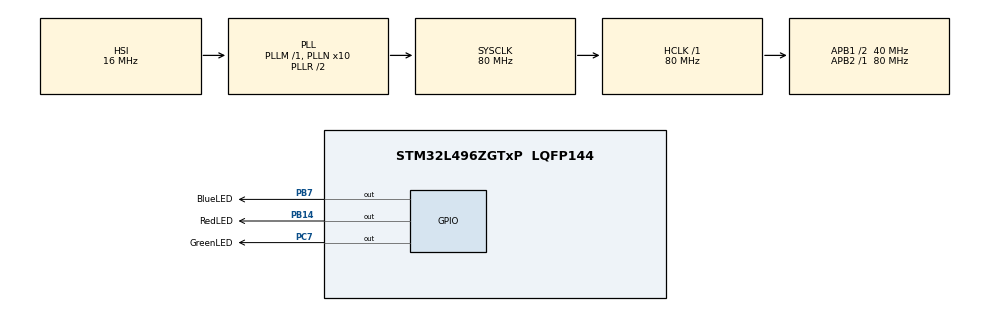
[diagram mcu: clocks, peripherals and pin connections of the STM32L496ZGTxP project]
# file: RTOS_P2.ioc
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FREERTOS.Tasks01=Task1,8,128,StartTask1,Default,NULL,Dynamic,NULL,NULL;Task2,16,128,StartTask2,Default,NULL,Dynamic,NULL,NULL;Task3,24,128,StartTask3,Default,NULL,Dynamic,NULL,NULL;Task4,32,128,StartTask4,Default,NULL,Dynamic,NULL,NULL
FREERTOS.configUSE_NEWLIB_REENTRANT=1
Mcu.Family=STM32L4
Mcu.Name=STM32L496ZGTxP
Mcu.Package=LQFP144
NVIC.PriorityGroup=NVIC_PRIORITYGROUP_4
NVIC.TIM6_DAC_IRQn=true\:15\:0\:false\:false\:true\:false\:false\:true\:true
NVIC.TimeBase=TIM6_DAC_IRQn
NVIC.TimeBaseIP=TIM6
PA13\ (JTMS/SWDIO).Mode=Serial_Wire
PA13\ (JTMS/SWDIO).Signal=SYS_JTMS-SWDIO
PA14\ (JTCK/SWCLK).Mode=Serial_Wire
PA14\ (JTCK/SWCLK).Signal=SYS_JTCK-SWCLK
PB14.GPIO_Label=RedLED
PB14.Signal=GPIO_Output
PB7.GPIO_Label=BlueLED
PB7.Signal=GPIO_Output
PC7.GPIO_Label=GreenLED
PC7.Signal=GPIO_Output
ProjectManager.HeapSize=0x200
ProjectManager.StackSize=0x400
ProjectManager.TargetToolchain=STM32CubeIDE
RCC.48MHZClocksFreq_Value=24000000
RCC.ADCFreq_Value=64000000
RCC.AHBFreq_Value=80000000
RCC.APB1CLKDivider=RCC_HCLK_DIV2
RCC.APB1Freq_Value=40000000
RCC.APB1TimFreq_Value=80000000
RCC.APB2Freq_Value=80000000
RCC.APB2TimFreq_Value=80000000
RCC.CortexFreq_Value=80000000
RCC.HCLKFreq_Value=80000000
RCC.HSE_VALUE=8000000
RCC.HSI48_VALUE=48000000
RCC.HSI_VALUE=16000000
RCC.LSE_VALUE=32768
RCC.MSI_VALUE=4000000
RCC.PLLMUL=RCC_PLL_MUL9
RCC.PLLN=10
RCC.PLLSourceVirtual=RCC_PLLSOURCE_HSI
RCC.PRESCALERUSB=RCC_USBCLKSOURCE_PLL_DIV1_5
RCC.SYSCLKFreq_VALUE=80000000
RCC.SYSCLKSource=RCC_SYSCLKSOURCE_PLLCLK
RCC.SYSCLKSourceVirtual=RCC_SYSCLKSOURCE_PLLCLK
RCC.USBFreq_Value=64000000
RCC.VCOOutputFreq_Value=160000000
VP_FREERTOS_VS_CMSIS_V2.Mode=CMSIS_V2
VP_SYS_VS_tim6.Mode=TIM6
board=NUCLEO-L496ZG-P

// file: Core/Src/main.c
/* USER CODE BEGIN Header */
/**
  ******************************************************************************
  * @file           : main.c
  * @brief          : Main program body
  ******************************************************************************
  * @attention
  *
  * Copyright (c) 2026 STMicroelectronics.
  * All rights reserved.
  *
  * This software is licensed under terms that can be found in the LICENSE file
  * in the root directory of this software component.
  * If no LICENSE file comes with this software, it is provided AS-IS.
  *
  ******************************************************************************
  */
/* USER CODE END Header */
#include "main.h"
#include "cmsis_os.h"

/* Definitions for Task1 */
osThreadId_t Task1Handle;
const osThreadAttr_t Task1_attributes = {
  .name = "Task1",
  .stack_size = 128 * 4,
  .priority = (osPriority_t) osPriorityLow,
};
/* Definitions for Task2 */
osThreadId_t Task2Handle;
const osThreadAttr_t Task2_attributes = {
  .name = "Task2",
  .stack_size = 128 * 4,
  .priority = (osPriority_t) osPriorityBelowNormal,
};
/* Definitions for Task3 */
osThreadId_t Task3Handle;
const osThreadAttr_t Task3_attributes = {
  .name = "Task3",
  .stack_size = 128 * 4,
  .priority = (osPriority_t) osPriorityNormal,
};
/* Definitions for Task4 */
osThreadId_t Task4Handle;
const osThreadAttr_t Task4_attributes = {
  .name = "Task4",
  .stack_size = 128 * 4,
  .priority = (osPriority_t) osPriorityAboveNormal,
};

void SystemClock_Config(void);
static void MX_GPIO_Init(void);
void StartTask1(void *argument);
void StartTask2(void *argument);
void StartTask3(void *argument);
void StartTask4(void *argument);

int main(void)
{

  /* MCU Configuration--------------------------------------------------------*/

  /* Reset of all peripherals, Initializes the Flash interface and the Systick. */
  HAL_Init();

  /* Configure the system clock */
  SystemClock_Config();

  /* Initialize all configured peripherals */
  MX_GPIO_Init();

  /* Init scheduler */
  osKernelInitialize();

  /* Create the thread(s) */
  /* creation of Task1 */
  Task1Handle = osThreadNew(StartTask1, NULL, &Task1_attributes);

  /* creation of Task2 */
  Task2Handle = osThreadNew(StartTask2, NULL, &Task2_attributes);

  /* creation of Task3 */
  Task3Handle = osThreadNew(StartTask3, NULL, &Task3_attributes);

  /* creation of Task4 */
  Task4Handle = osThreadNew(StartTask4, NULL, &Task4_attributes);

  /* Start scheduler */
  osKernelStart();

  /* We should never get here as control is now taken by the scheduler */

  /* Infinite loop */
  while (1)
  {

  }
}

void SystemClock_Config(void)
{
  RCC_OscInitTypeDef RCC_OscInitStruct = {0};
  RCC_ClkInitTypeDef RCC_ClkInitStruct = {0};

  /** Configure the main internal regulator output voltage
  */
  if (HAL_PWREx_ControlVoltageScaling(PWR_REGULATOR_VOLTAGE_SCALE1) != HAL_OK)
  {
    Error_Handler();
  }

  /** Initializes the RCC Oscillators according to the specified parameters
  * in the RCC_OscInitTypeDef structure.
  */
  RCC_OscInitStruct.OscillatorType = RCC_OSCILLATORTYPE_HSI;
  RCC_OscInitStruct.HSIState = RCC_HSI_ON;
  RCC_OscInitStruct.HSICalibrationValue = RCC_HSICALIBRATION_DEFAULT;
  RCC_OscInitStruct.PLL.PLLState = RCC_PLL_ON;
  RCC_OscInitStruct.PLL.PLLSource = RCC_PLLSOURCE_HSI;
  RCC_OscInitStruct.PLL.PLLM = 1;
  RCC_OscInitStruct.PLL.PLLN = 10;
  RCC_OscInitStruct.PLL.PLLP = RCC_PLLP_DIV2;
  RCC_OscInitStruct.PLL.PLLQ = RCC_PLLQ_DIV2;
  RCC_OscInitStruct.PLL.PLLR = RCC_PLLR_DIV2;
  if (HAL_RCC_OscConfig(&RCC_OscInitStruct) != HAL_OK)
  {
    Error_Handler();
  }

  /** Initializes the CPU, AHB and APB buses clocks
  */
  RCC_ClkInitStruct.ClockType = RCC_CLOCKTYPE_HCLK|RCC_CLOCKTYPE_SYSCLK
                              |RCC_CLOCKTYPE_PCLK1|RCC_CLOCKTYPE_PCLK2;
  RCC_ClkInitStruct.SYSCLKSource = RCC_SYSCLKSOURCE_PLLCLK;
  RCC_ClkInitStruct.AHBCLKDivider = RCC_SYSCLK_DIV1;
  RCC_ClkInitStruct.APB1CLKDivider = RCC_HCLK_DIV2;
  RCC_ClkInitStruct.APB2CLKDivider = RCC_HCLK_DIV1;

  if (HAL_RCC_ClockConfig(&RCC_ClkInitStruct, FLASH_LATENCY_4) != HAL_OK)
  {
    Error_Handler();
  }
}

static void MX_GPIO_Init(void)
{
  GPIO_InitTypeDef GPIO_InitStruct = {0};

  /* GPIO Ports Clock Enable */
  __HAL_RCC_GPIOB_CLK_ENABLE();
  __HAL_RCC_GPIOC_CLK_ENABLE();
  __HAL_RCC_GPIOA_CLK_ENABLE();

  /*Configure GPIO pin Output Level */
  HAL_GPIO_WritePin(GPIOB, RedLED_Pin|BlueLED_Pin, GPIO_PIN_RESET);

  /*Configure GPIO pin Output Level */
  HAL_GPIO_WritePin(GreenLED_GPIO_Port, GreenLED_Pin, GPIO_PIN_RESET);

  /*Configure GPIO pins : RedLED_Pin BlueLED_Pin */
  GPIO_InitStruct.Pin = RedLED_Pin|BlueLED_Pin;
  GPIO_InitStruct.Mode = GPIO_MODE_OUTPUT_PP;
  GPIO_InitStruct.Pull = GPIO_NOPULL;
  GPIO_InitStruct.Speed = GPIO_SPEED_FREQ_LOW;
  HAL_GPIO_Init(GPIOB, &GPIO_InitStruct);

  /*Configure GPIO pin : GreenLED_Pin */
  GPIO_InitStruct.Pin = GreenLED_Pin;
  GPIO_InitStruct.Mode = GPIO_MODE_OUTPUT_PP;
  GPIO_InitStruct.Pull = GPIO_NOPULL;
  GPIO_InitStruct.Speed = GPIO_SPEED_FREQ_LOW;
  HAL_GPIO_Init(GreenLED_GPIO_Port, &GPIO_InitStruct);

}

void StartTask1(void *argument)
{
  /* USER CODE BEGIN 5 */

  /* Infinite loop */
  for(;;)
  {
      volatile uint32_t wait = 50000000;
	  HAL_GPIO_TogglePin(RedLED_GPIO_Port, RedLED_Pin);
	  osDelay(1000);
	  while (wait--);
  }
  /* USER CODE END 5 */
}

void StartTask2(void *argument)
{
  /* USER CODE BEGIN StartTask2 */
  /* Infinite loop */
  for(;;)
  {
	  HAL_GPIO_TogglePin(BlueLED_GPIO_Port, BlueLED_Pin);
	  osDelay(500);
  }
  /* USER CODE END StartTask2 */
}

void StartTask3(void *argument)
{
  /* USER CODE BEGIN StartTask3 */
  /* Infinite loop */
  for(;;)
  {
	  volatile uint32_t wait = 50000000;
	  HAL_GPIO_TogglePin(GreenLED_GPIO_Port, GreenLED_Pin);
	  osDelay(200);
	  while (wait--);
  }
  /* USER CODE END StartTask3 */
}

void StartTask4(void *argument)
{
  /* USER CODE BEGIN StartTask4 */
  /* Infinite loop */
  for(;;)
  {
	  osDelay(1000);
	  osThreadSuspend(Task3Handle);
	  osDelay(5000);
	  osThreadResume(Task3Handle);
  }
  /* USER CODE END StartTask4 */
}

void HAL_TIM_PeriodElapsedCallback(TIM_HandleTypeDef *htim)
{
  if (htim->Instance == TIM6)
  {
    HAL_IncTick();
  }
}

void Error_Handler(void)
{
  __disable_irq();
  while (1)
  {
  }
}
